# M344 register map
File version: 2.0.2.6
TOSHIBA Cortex-M3 MCU
Registers are 32-bit, read-write, reset 0x0 unless marked. A register's access mark holds for its fields unless they carry their own. Offsets are from the block's base; lines under a group give offsets from that group; [hi:lo] are bit positions; {n}, {i} and the like mark numbered series; 'fields as' and 'values as' point back to an identical list; <NAME> marks a mode.

## Memory map
0x40000000 DMACA blocks up to offset 0x134 — DMA Controller
0x40001000 DMACB blocks up to offset 0x134
0x40002000 DMACC blocks up to offset 0x134
0x40050000 ADA blocks up to offset 0x7C — 12bit A_D Converter
0x40051000 ADB blocks up to offset 0x7C
0x40052000 ADC blocks up to offset 0x7C
0x40060000 EPHC0 blocks up to offset 0x78 — Enhannced two aspect pulse input counter (EPHC)
0x40061000 EPHC1 blocks up to offset 0x78
0x4007E000 EPHC2 blocks up to offset 0x78
0x4009B000 TSPI3 blocks up to offset 0x208 — Serial Interface (TSPI)
0x4009C000 TSPI4 blocks up to offset 0x208
0x400C0000 PA blocks up to offset 0x3C — Port A
0x400C0100 PB blocks up to offset 0x3C — Port B
0x400C0200 PC blocks up to offset 0x3C — Port C
0x400C0300 PD blocks up to offset 0x3C — Port D
0x400C0400 PE blocks up to offset 0x3C — Port E
0x400C0500 PF blocks up to offset 0x3C — Port F
0x400C0600 PG blocks up to offset 0x3C — Port G
0x400C0700 PH blocks up to offset 0x3C — Port H
0x400C0800 PJ blocks up to offset 0x3C — Port J
0x400C0900 PK size 0x14 — Port K
0x400C0A00 PL size 0x14 — Port L
0x400C0B00 PM blocks up to offset 0x30 — Port M
0x400C0C00 PN blocks up to offset 0x3C — Port N
0x400E0000 SBI size 0x18 — Serial Bus Interface (SBI)
0x400E1000 SC size 0x38 — Serial Channel (SC)
0x400F2000 WD size 0x8 — Watchdog Timer (WD)
0x400F3000 CG blocks up to offset 0x6C — Clock Generator (CG)
0x40118000 PSCA blocks up to offset 0x710C — Programmable Servo Controller
0x40158000 TD0A blocks up to offset 0x168 — Timer D (Unit0)
0x4015802C TD1A blocks up to offset 0x144 — Timer D (Unit1)
0x40158040 TDA blocks up to offset 0x18 — Timer D common
0x40175000 EPHC0_PSC blocks up to offset 0x70 — Enhannced two aspect pulse input counter (EPHC) Mirror
0x40179000 ADB_PSC blocks up to offset 0x7C — 12-bit AD converter(UnitB) Mirror
0x4017C000 EPHC2_PSC blocks up to offset 0x70 — Enhannced two aspect pulse input counter (EPHC) Mirror
0x401C4C00 TBC size 0x34 — 16-bit Timer_Event Counter (TB)
0x401C4D00 TBD size 0x34
0x40218000 PSCB blocks up to offset 0x710C
0x40276000 EPHC1_PSC blocks up to offset 0x70 — Enhannced two aspect pulse input counter (EPHC) Mirror
0x4027A000 ADC_PSC blocks up to offset 0x7C — 12-bit AD converter(UnitC) Mirror
0x40299000 TSPI1 blocks up to offset 0x208
0x402C4E00 TBE size 0x34
0x402C4F00 TBF size 0x34
0x40318000 PSCC blocks up to offset 0x710C
0x40359000 TD0B blocks up to offset 0x168
0x4035902C TD1B blocks up to offset 0x144
0x40359040 TDB blocks up to offset 0x18
0x40374000 ADA_PSC blocks up to offset 0x7C — 12-bit AD converter(UnitA) Mirror
0x4039A000 TSPI2 blocks up to offset 0x208
{0x403C4000+0x100*n} TB{n} size 0x34 (n=0..9)
0x403C4A00 TBA size 0x34
0x403C4B00 TBB size 0x34
0x40418000 PSCD blocks up to offset 0x710C
0x40448000 UART blocks up to offset 0x4C
0x40498000 TSPI0 blocks up to offset 0x208
0x5DFF0000 FC blocks up to offset 0x15C — Flash Control (FC)

## DMACA — DMA Controller
Base 0x40000000
Same registers: DMACB 0x40001000, DMACC 0x40002000
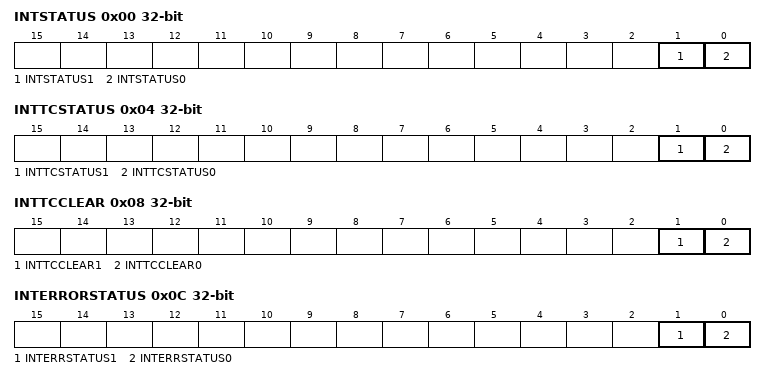
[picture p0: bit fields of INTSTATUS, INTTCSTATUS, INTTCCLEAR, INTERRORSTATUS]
0x00 INTSTATUS ro — DMAC Interrupt Status Register
  [1] INTSTATUS1, [0] INTSTATUS0
0x04 INTTCSTATUS ro — DMAC Interrupt Terminal Count Status Register
  [1] INTTCSTATUS1, [0] INTTCSTATUS0
0x08 INTTCCLEAR wo — DMAC Interrupt Terminal Count Clear Register
  [1] INTTCCLEAR1, [0] INTTCCLEAR0
0x0C INTERRORSTATUS ro — DMAC Interrupt Error Status Register
  [1] INTERRSTATUS1, [0] INTERRSTATUS0
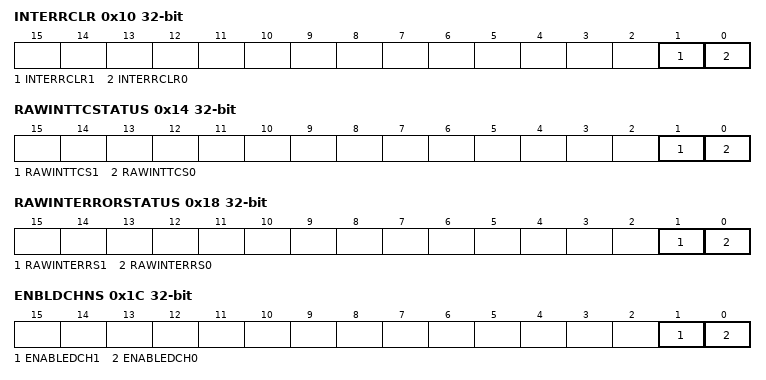
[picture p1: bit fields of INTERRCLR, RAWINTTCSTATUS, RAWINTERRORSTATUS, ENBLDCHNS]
0x10 INTERRCLR wo — DMAC Interrupt Error Clear Register
  [1] INTERRCLR1, [0] INTERRCLR0
0x14 RAWINTTCSTATUS ro — DMAC Raw Interrupt Terminal Count Status Register
  [1] RAWINTTCS1, [0] RAWINTTCS0
0x18 RAWINTERRORSTATUS ro — DMAC Raw Error Interrupt Status Register
  [1] RAWINTERRS1, [0] RAWINTERRS0
0x1C ENBLDCHNS ro — DMAC Enabled Channel Register
  [1] ENABLEDCH1, [0] ENABLEDCH0
0x20 SOFTBREQ — DMAC Software Burst Request Register
  [15:0] SOFTBREQ
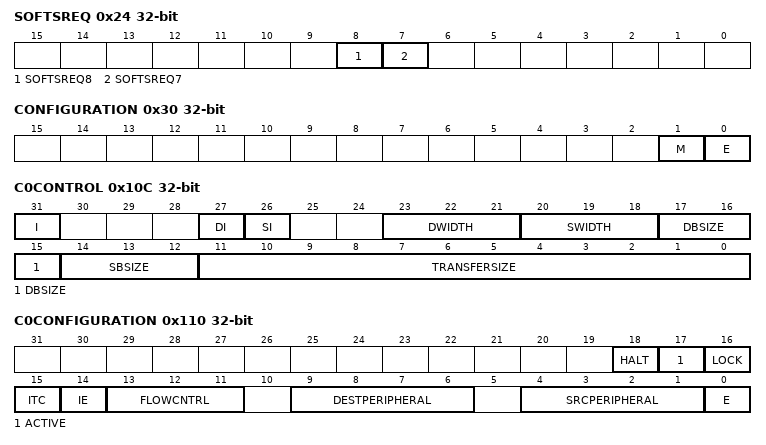
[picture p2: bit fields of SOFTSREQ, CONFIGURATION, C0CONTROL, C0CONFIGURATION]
0x24 SOFTSREQ — DMAC Software Single Request Register
  [8] SOFTSREQ8, [7] SOFTSREQ7
0x30 CONFIGURATION — DMAC Configuration Register
  [1] M, [0] E
0x100 C0SRCADDR — DMAC Channel 0 Source Address Register
  [31:0] SRCADDR
0x104 C0DESTADDR — DMAC Channel 0 Destination Address Register
  [31:0] DESTADDR
0x108 C0LLI — DMAC Channel 0 Linked List Item Register
  [31:2] LLI
0x10C C0CONTROL — DMAC Channel 0 Control Register
  [31] I, [27] DI, [26] SI, [23:21] DWIDTH, [20:18] SWIDTH, [17:15] DBSIZE, [14:12] SBSIZE, [11:0] TRANSFERSIZE
0x110 C0CONFIGURATION (reset mask 0x7FBDE) — DMAC Channel 0 Configuration Register
  [18] HALT, [17] ACTIVE ro, [16] LOCK, [15] ITC, [14] IE, [13:11] FLOWCNTRL, [9:6] DESTPERIPHERAL, [4:1] SRCPERIPHERAL, [0] E
0x120 C1SRCADDR — DMAC Channel 1 Source Address Register
  [31:0] SRCADDR
0x124 C1DESTADDR — DMAC Channel 1 Destination Address Register
  [31:0] DESTADDR
0x128 C1LLI — DMAC Channel 1 Linked List Item Register
  [31:2] LLI
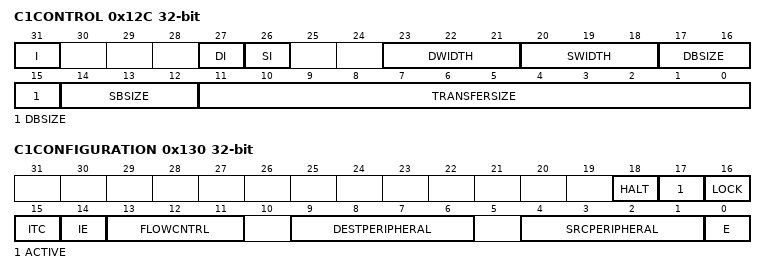
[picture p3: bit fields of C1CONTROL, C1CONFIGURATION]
0x12C C1CONTROL — DMAC Channel 1 Control Register
  fields as C0CONTROL
0x130 C1CONFIGURATION (reset mask 0x7FBDE) — DMAC Channel 1 Configuration Register
  fields as C0CONFIGURATION
